# nrf9230_engb_isimcore register map
Vendor: Nordic Semiconductor; Series: nRF92; File version: 1
CPU: CM0 r0p1, little endian, MPU, no FPU, 2 interrupt priority bits, 32 interrupts
Registers are 32-bit, read-write, reset 0x0 unless marked. A register's access mark holds for its fields unless they carry their own. Offsets are from the block's base; [hi:lo] are bit positions; {n}, {i} and the like mark numbered series; 'fields as' and 'values as' point back to an identical list.

## MHU0RCV_NS — Message handling unit receiver (MHURCV) 0
Base 0x47022000
Same registers: MHU1RCV_NS 0x47024000, MHU0RCV_S 0x57022000, MHU1RCV_S 0x57024000
{0x0+0x20*i} REG_{i}_STAT ro (i=0..7) — Receiver message status register before the mask
{0x4+0x20*i} REG_{i}_STAT_PEND ro (i=0..7) — Receiver message status register after the mask
{0x8+0x20*i} REG_{i}_STAT_CLEAR wo (i=0..7) — Receiver message clear status register
  [31:0] REG_{i}_STAT_CLEAR — Message Clear status register. Clearing the message also clears the corresponding interrupt.
{0x10+0x20*i} REG_{i}_MASK ro (i=0..7) — Receiver message mask register
{0x14+0x20*i} REG_{i}_MASK_SET wo (i=0..6) — Receiver message mask set register
{0x18+0x20*i} REG_{i}_MASK_CLEAR wo (i=0..7) — Receiver message mask clear register
0xF4 REG_7_MASK_SET wo — Receiver message mask set register
  [31:0] REG7_MASK_SET
0xF80 MSG_NO_CAP ro reset 0x8 — Receiver control register for number of message communication channels configured, between 1 and 124
  [6:0] MSG_NO_CAP — Number of message communication channels
0xFD0 PID4 ro reset 0x4 — Receiver Peripheral ID 4
  [7:0] PID4 — Sender Peripheral ID 4
0xFE0 PID0 ro reset 0xD1 — Receiver Peripheral ID 0
  [7:0] PID0 — Sender Peripheral ID 0
0xFE4 PID1 ro reset 0xB0 — Receiver Peripheral ID 1
  [7:0] PID1 — Sender Peripheral ID 1
0xFE8 PID2 ro reset 0xB — Receiver Peripheral ID 2
  [7:0] PID2 — Sender Peripheral ID 2
0xFEC PID3 ro — Receiver Peripheral ID 3
  [7:0] PID3 — Sender Peripheral ID 3
0xFF0 COMPID0 ro reset 0xD — Component ID 0
  [7:0] COMPID0
0xFF4 COMPID1 ro reset 0xF0 — Component ID 1
  [7:0] COMPID1
0xFF8 COMPID2 ro reset 0x5 — Component ID 2
  [7:0] COMPID2
0xFFC COMPID3 ro reset 0xB1 — Component ID 3
  [7:0] COMPID3

## GLOBAL_TBM_NS — Trace buffer monitor 0
Base 0xBF003000
Same registers: GLOBAL_TBM_S 0xBF003000 (alternate view of GLOBAL_TBM_NS)
0x00 TASKS_START wo — Start counter
  [0] TASKS_START
    1=Trigger task
0x04 TASKS_STOP wo — Stop counter, clear counter value
  [0] TASKS_STOP
    1=Trigger task
0x08 TASKS_FLUSH wo — Save current counter value to COUNTSNAPSHOT
  [0] TASKS_FLUSH
    1=Trigger task
0x100 EVENTS_HALFFULL — Counter value equals half-full
  [0] EVENTS_HALFFULL
    0=NotGenerated (Event not generated); 1=Generated (Event generated)
0x104 EVENTS_FULL — Counter value equals full
  [0] EVENTS_FULL
    values as EVENTS_HALFFULL.EVENTS_HALFFULL
0x108 EVENTS_FLUSH — Counter value saved to COUNTSNAPSHOT due to flush
  [0] EVENTS_FLUSH
    values as EVENTS_HALFFULL.EVENTS_HALFFULL
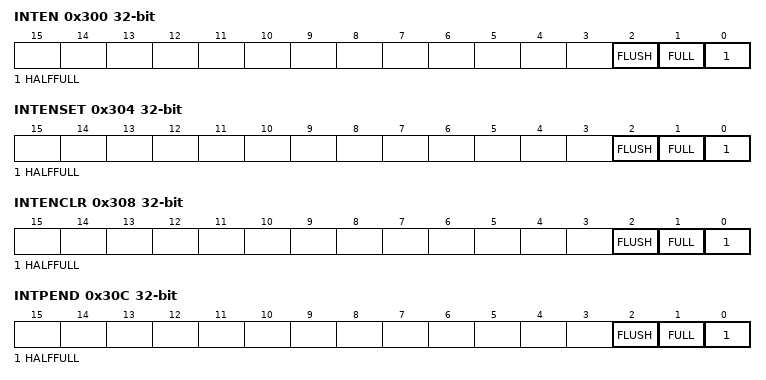
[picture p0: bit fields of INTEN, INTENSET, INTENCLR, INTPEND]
0x300 INTEN — Enable or disable interrupt
  [all] fields
    0=Disabled; 1=Enabled
  [2] FLUSH — Enable or disable interrupt for event FLUSH
  [1] FULL — Enable or disable interrupt for event FULL
  [0] HALFFULL — Enable or disable interrupt for event HALFFULL
0x304 INTENSET — Enable interrupt
  [all] fields
    on read: 0=Disabled (Read: Disabled); 1=Enabled (Read: Enabled) | on write: 1=Set (Enable)
  [2] FLUSH — Write '1' to enable interrupt for event FLUSH
  [1] FULL — Write '1' to enable interrupt for event FULL
  [0] HALFFULL — Write '1' to enable interrupt for event HALFFULL
0x308 INTENCLR — Disable interrupt
  [all] fields
    on read: 0=Disabled (Read: Disabled); 1=Enabled (Read: Enabled) | on write: 1=Clear (Disable)
  [2] FLUSH — Write '1' to disable interrupt for event FLUSH
  [1] FULL — Write '1' to disable interrupt for event FULL
  [0] HALFFULL — Write '1' to disable interrupt for event HALFFULL
0x30C INTPEND ro — Pending interrupts
  [all] fields
    on read: 0=NotPending (Read: Not pending); 1=Pending (Read: Pending)
  [2] FLUSH — Read pending status of interrupt for event FLUSH
  [1] FULL — Read pending status of interrupt for event FULL
  [0] HALFFULL — Read pending status of interrupt for event HALFFULL
0x400 BUFFERSIZE reset 0x400 — System RAM trace buffer total size in bytes
  [12:0] BUFFERSIZE — Must only be configured in STOP mode. Must be programmed to multiple of 16 bytes to make half-buffer size always 64 bit word aligned. Typical minimum BUFFERSIZE value 0x010 i.e. 16 bytes, typical maximum value 0x1000 i.e. 4096 bytes.
    0=Zero (0 bytes); 16=Min (16 bytes); 0x1000=Max (4096 bytes)
0x404 COUNT — Counter current value
  [12:0] COUNT — Counter current value. Only writable when counter is in stopped state. Writing when not in stopped state will generate a bus fault.
0x408 COUNTSNAPSHOT ro — Copy of the current COUNT value
  [12:0] COUNTSNAPSHOT — TASKS_FLUSH will copy the current COUNT value to this register.
